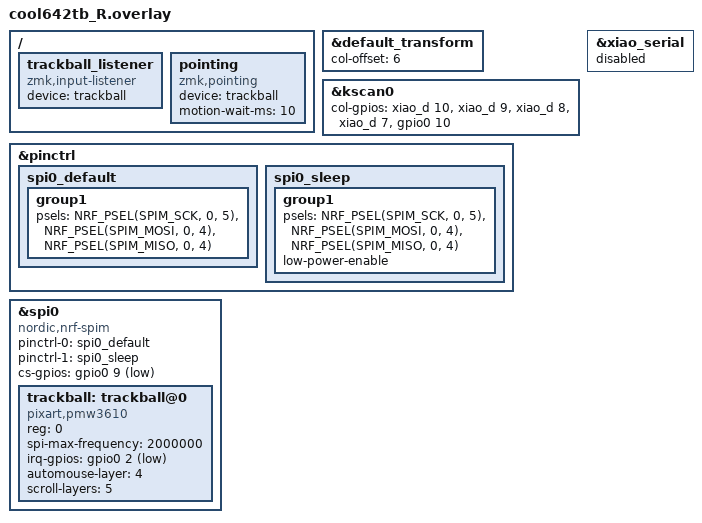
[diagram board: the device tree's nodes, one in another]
#include "cool642tb.dtsi"

&default_transform {
    col-offset = <6>;
};

&kscan0 {
        col-gpios
            = <&xiao_d 10 GPIO_ACTIVE_HIGH>
            , <&xiao_d 9 GPIO_ACTIVE_HIGH> 
            , <&xiao_d 8 GPIO_ACTIVE_HIGH> 
            , <&xiao_d 7 GPIO_ACTIVE_HIGH> 
            , <&gpio0 10 GPIO_ACTIVE_HIGH>
            ;
};

/ {
    trackball_listener {
        compatible = "zmk,input-listener";
        device = <&trackball>;

    };

    pointing: pointing {
        compatible = "zmk,pointing"; // ZMKのポインティングデバイス互換性
        status = "okay"; // このノードを有効にする

        // ポインティングサブシステムがどのハードウェアデバイスを使うかを指定
        device = <&trackball>; // trackball: trackball@0 ノードを参照

        // ★★ ここに motion-wait-ms を設定 ★★
        motion-wait-ms = 10; // 例: 50ミリ秒。この値を調整してください。

        // 必要に応じて他のポインティング関連設定を追加
        // sensitivity = ; // 例: 感度調整（カーソル移動量）
        // incline = ;       // 例: インクライン調整（トラックボールでは通常0）
    };
};

&pinctrl {
    spi0_default: spi0_default {
        group1 {
            psels = <NRF_PSEL(SPIM_SCK, 0, 5)>,
                <NRF_PSEL(SPIM_MOSI, 0, 4)>,
                <NRF_PSEL(SPIM_MISO, 0, 4)>;
        };
    };

    spi0_sleep: spi0_sleep {
        group1 {
            psels = <NRF_PSEL(SPIM_SCK, 0, 5)>,
                <NRF_PSEL(SPIM_MOSI, 0, 4)>,
                <NRF_PSEL(SPIM_MISO, 0, 4)>;
            low-power-enable;
        };
    };
};

&xiao_serial { status = "disabled"; };

&spi0 {
    status = "okay";
    compatible = "nordic,nrf-spim";
    pinctrl-0 = <&spi0_default>;
    pinctrl-1 = <&spi0_sleep>;
    pinctrl-names = "default", "sleep";
    cs-gpios = <&gpio0 9 GPIO_ACTIVE_LOW>;

    trackball: trackball@0 {
        status = "okay";
        compatible = "pixart,pmw3610";
        reg = <0>;
        spi-max-frequency = <2000000>;
        irq-gpios = <&gpio0 2 (GPIO_ACTIVE_LOW | GPIO_PULL_UP)>;
        automouse-layer = <4>;
        scroll-layers = <5>;
    };
};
